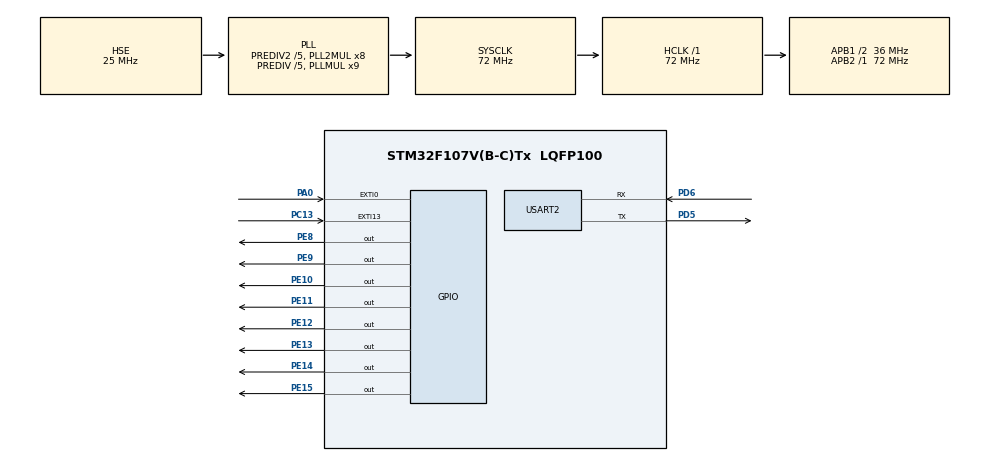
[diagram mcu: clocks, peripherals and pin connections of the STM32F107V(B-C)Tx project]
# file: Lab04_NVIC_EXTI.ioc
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Mcu.Family=STM32F1
Mcu.Name=STM32F107V(B-C)Tx
Mcu.Package=LQFP100
NVIC.EXTI0_IRQn=true\:2\:1\:true\:false\:true\:true
NVIC.EXTI15_10_IRQn=true\:1\:3\:true\:false\:true\:true
NVIC.PriorityGroup=NVIC_PRIORITYGROUP_2
OSC_IN.Mode=HSE-External-Oscillator
OSC_IN.Signal=RCC_OSC_IN
OSC_OUT.Mode=HSE-External-Oscillator
OSC_OUT.Signal=RCC_OSC_OUT
PA0-WKUP.Signal=GPXTI0
PC13-TAMPER-RTC.GPIO_ModeDefaultEXTI=GPIO_MODE_IT_FALLING
PC13-TAMPER-RTC.Signal=GPXTI13
PD5.Mode=Asynchronous
PD5.Signal=USART2_TX
PD6.Mode=Asynchronous
PD6.Signal=USART2_RX
PE10.GPIO_Speed=GPIO_SPEED_FREQ_HIGH
PE10.Signal=GPIO_Output
PE11.GPIO_Speed=GPIO_SPEED_FREQ_HIGH
PE11.Signal=GPIO_Output
PE12.GPIO_Speed=GPIO_SPEED_FREQ_HIGH
PE12.Signal=GPIO_Output
PE13.GPIO_Speed=GPIO_SPEED_FREQ_HIGH
PE13.Signal=GPIO_Output
PE14.GPIO_Speed=GPIO_SPEED_FREQ_HIGH
PE14.Signal=GPIO_Output
PE15.GPIO_Speed=GPIO_SPEED_FREQ_HIGH
PE15.Signal=GPIO_Output
PE8.GPIO_Speed=GPIO_SPEED_FREQ_HIGH
PE8.Signal=GPIO_Output
PE9.GPIO_Speed=GPIO_SPEED_FREQ_HIGH
PE9.Signal=GPIO_Output
ProjectManager.HeapSize=0x200
ProjectManager.StackSize=0x400
ProjectManager.TargetToolchain=MDK-ARM V5
RCC.AHBFreq_Value=72000000
RCC.APB1CLKDivider=RCC_HCLK_DIV2
RCC.APB1Freq_Value=36000000
RCC.APB1TimFreq_Value=72000000
RCC.APB2Freq_Value=72000000
RCC.APB2TimFreq_Value=72000000
RCC.HCLKFreq_Value=72000000
RCC.HSEDivPLL=RCC_HSE_PREDIV_DIV5
RCC.HSE_VALUE=25000000
RCC.PLLMUL=RCC_PLL_MUL9
RCC.PLLSourceVirtual=RCC_PLLSOURCE_HSE
RCC.Prediv1Source=RCC_PREDIV1_SOURCE_PLL2
RCC.Prediv2=RCC_HSE_PREDIV2_DIV5
RCC.SYSCLKFreq_VALUE=72000000
RCC.SYSCLKSource=RCC_SYSCLKSOURCE_PLLCLK
RCC.USBFreq_Value=48000000
USART2.VirtualMode=VM_ASYNC
VP_SYS_VS_ND.Mode=No_Debug
board=Lab04_NVIC_EXTI

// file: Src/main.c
/**
  ******************************************************************************
  * File Name          : main.c
  * Description        : Main program body
  ******************************************************************************
  ** This notice applies to any and all portions of this file
  * that are not between comment pairs USER CODE BEGIN and
  * USER CODE END. Other portions of this file, whether
  * inserted by the user or by software development tools
  * are owned by their respective copyright owners.
  *
  * COPYRIGHT(c) 2018 STMicroelectronics
  *
  * Redistribution and use in source and binary forms, with or without modification,
  * are permitted provided that the following conditions are met:
  *   1. Redistributions of source code must retain the above copyright notice,
  *      this list of conditions and the following disclaimer.
  *   2. Redistributions in binary form must reproduce the above copyright notice,
  *      this list of conditions and the following disclaimer in the documentation
  *      and/or other materials provided with the distribution.
  *   3. Neither the name of STMicroelectronics nor the names of its contributors
  *      may be used to endorse or promote products derived from this software
  *      without specific prior written permission.
  *
  * THIS SOFTWARE IS PROVIDED BY THE COPYRIGHT HOLDERS AND CONTRIBUTORS "AS IS"
  * AND ANY EXPRESS OR IMPLIED WARRANTIES, INCLUDING, BUT NOT LIMITED TO, THE
  * IMPLIED WARRANTIES OF MERCHANTABILITY AND FITNESS FOR A PARTICULAR PURPOSE ARE
  * DISCLAIMED. IN NO EVENT SHALL THE COPYRIGHT HOLDER OR CONTRIBUTORS BE LIABLE
  * FOR ANY DIRECT, INDIRECT, INCIDENTAL, SPECIAL, EXEMPLARY, OR CONSEQUENTIAL
  * DAMAGES (INCLUDING, BUT NOT LIMITED TO, PROCUREMENT OF SUBSTITUTE GOODS OR
  * SERVICES; LOSS OF USE, DATA, OR PROFITS; OR BUSINESS INTERRUPTION) HOWEVER
  * CAUSED AND ON ANY THEORY OF LIABILITY, WHETHER IN CONTRACT, STRICT LIABILITY,
  * OR TORT (INCLUDING NEGLIGENCE OR OTHERWISE) ARISING IN ANY WAY OUT OF THE USE
  * OF THIS SOFTWARE, EVEN IF ADVISED OF THE POSSIBILITY OF SUCH DAMAGE.
  *
  ******************************************************************************
  */

#include "main.h"
#include "stm32f1xx_hal.h"

UART_HandleTypeDef huart2;

/* USER CODE BEGIN PV */
/* Private variables ---------------------------------------------------------*/

/* USER CODE END PV */

void SystemClock_Config(void);
static void MX_GPIO_Init(void);
static void MX_USART2_UART_Init(void);

/* USER CODE BEGIN PFP */
/* Private function prototypes -----------------------------------------------*/

/* USER CODE END PFP */

int main(void)
{

  /* MCU Configuration----------------------------------------------------------*/

  /* Reset of all peripherals, Initializes the Flash interface and the Systick. */
  HAL_Init();

  /* Configure the system clock */
  SystemClock_Config();

  /* Initialize all configured peripherals */
  MX_GPIO_Init();
  MX_USART2_UART_Init();

  /* USER CODE BEGIN 2 */
	GPIOE->ODR = 0x0000;
  /* USER CODE END 2 */

  /* Infinite loop */
  while (1)
  {

  /* USER CODE BEGIN 3 */
	HAL_UART_Transmit(&huart2, (uint8_t*)"x", 1, 100);
	HAL_Delay(300);
  }
  /* USER CODE END 3 */

}

/** System Clock Configuration
*/
void SystemClock_Config(void)
{

  RCC_OscInitTypeDef RCC_OscInitStruct;
  RCC_ClkInitTypeDef RCC_ClkInitStruct;

    /**Initializes the CPU, AHB and APB busses clocks
    */
  RCC_OscInitStruct.OscillatorType = RCC_OSCILLATORTYPE_HSE;
  RCC_OscInitStruct.HSEState = RCC_HSE_ON;
  RCC_OscInitStruct.HSEPredivValue = RCC_HSE_PREDIV_DIV5;
  RCC_OscInitStruct.HSIState = RCC_HSI_ON;
  RCC_OscInitStruct.Prediv1Source = RCC_PREDIV1_SOURCE_PLL2;
  RCC_OscInitStruct.PLL.PLLState = RCC_PLL_ON;
  RCC_OscInitStruct.PLL.PLLSource = RCC_PLLSOURCE_HSE;
  RCC_OscInitStruct.PLL.PLLMUL = RCC_PLL_MUL9;
  RCC_OscInitStruct.PLL2.PLL2State = RCC_PLL2_ON;
  RCC_OscInitStruct.PLL2.PLL2MUL = RCC_PLL2_MUL8;
  RCC_OscInitStruct.PLL2.HSEPrediv2Value = RCC_HSE_PREDIV2_DIV5;
  if (HAL_RCC_OscConfig(&RCC_OscInitStruct) != HAL_OK)
  {
    _Error_Handler(__FILE__, __LINE__);
  }

    /**Initializes the CPU, AHB and APB busses clocks
    */
  RCC_ClkInitStruct.ClockType = RCC_CLOCKTYPE_HCLK|RCC_CLOCKTYPE_SYSCLK
                              |RCC_CLOCKTYPE_PCLK1|RCC_CLOCKTYPE_PCLK2;
  RCC_ClkInitStruct.SYSCLKSource = RCC_SYSCLKSOURCE_PLLCLK;
  RCC_ClkInitStruct.AHBCLKDivider = RCC_SYSCLK_DIV1;
  RCC_ClkInitStruct.APB1CLKDivider = RCC_HCLK_DIV2;
  RCC_ClkInitStruct.APB2CLKDivider = RCC_HCLK_DIV1;

  if (HAL_RCC_ClockConfig(&RCC_ClkInitStruct, FLASH_LATENCY_2) != HAL_OK)
  {
    _Error_Handler(__FILE__, __LINE__);
  }

    /**Configure the Systick interrupt time
    */
  HAL_SYSTICK_Config(HAL_RCC_GetHCLKFreq()/1000);

    /**Configure the Systick
    */
  HAL_SYSTICK_CLKSourceConfig(SYSTICK_CLKSOURCE_HCLK);

    /**Configure the Systick interrupt time
    */
  __HAL_RCC_PLLI2S_ENABLE();

  /* SysTick_IRQn interrupt configuration */
  HAL_NVIC_SetPriority(SysTick_IRQn, 0, 0);
}

/* USART2 init function */
static void MX_USART2_UART_Init(void)
{

  huart2.Instance = USART2;
  huart2.Init.BaudRate = 115200;
  huart2.Init.WordLength = UART_WORDLENGTH_8B;
  huart2.Init.StopBits = UART_STOPBITS_1;
  huart2.Init.Parity = UART_PARITY_NONE;
  huart2.Init.Mode = UART_MODE_TX_RX;
  huart2.Init.HwFlowCtl = UART_HWCONTROL_NONE;
  huart2.Init.OverSampling = UART_OVERSAMPLING_16;
  if (HAL_UART_Init(&huart2) != HAL_OK)
  {
    _Error_Handler(__FILE__, __LINE__);
  }

}

/** Configure pins as
        * Analog
        * Input
        * Output
        * EVENT_OUT
        * EXTI
*/
static void MX_GPIO_Init(void)
{

  GPIO_InitTypeDef GPIO_InitStruct;

  /* GPIO Ports Clock Enable */
  __HAL_RCC_GPIOC_CLK_ENABLE();
  __HAL_RCC_GPIOA_CLK_ENABLE();
  __HAL_RCC_GPIOE_CLK_ENABLE();
  __HAL_RCC_GPIOD_CLK_ENABLE();

  /*Configure GPIO pin Output Level */
  HAL_GPIO_WritePin(GPIOE, GPIO_PIN_8|GPIO_PIN_9|GPIO_PIN_10|GPIO_PIN_11
                          |GPIO_PIN_12|GPIO_PIN_13|GPIO_PIN_14|GPIO_PIN_15, GPIO_PIN_RESET);

  /*Configure GPIO pin : PC13 */
  GPIO_InitStruct.Pin = GPIO_PIN_13;
  GPIO_InitStruct.Mode = GPIO_MODE_IT_FALLING;
  GPIO_InitStruct.Pull = GPIO_NOPULL;
  HAL_GPIO_Init(GPIOC, &GPIO_InitStruct);

  /*Configure GPIO pin : PA0 */
  GPIO_InitStruct.Pin = GPIO_PIN_0;
  GPIO_InitStruct.Mode = GPIO_MODE_IT_RISING;
  GPIO_InitStruct.Pull = GPIO_NOPULL;
  HAL_GPIO_Init(GPIOA, &GPIO_InitStruct);

  /*Configure GPIO pins : PE8 PE9 PE10 PE11
                           PE12 PE13 PE14 PE15 */
  GPIO_InitStruct.Pin = GPIO_PIN_8|GPIO_PIN_9|GPIO_PIN_10|GPIO_PIN_11
                          |GPIO_PIN_12|GPIO_PIN_13|GPIO_PIN_14|GPIO_PIN_15;
  GPIO_InitStruct.Mode = GPIO_MODE_OUTPUT_PP;
  GPIO_InitStruct.Speed = GPIO_SPEED_FREQ_HIGH;
  HAL_GPIO_Init(GPIOE, &GPIO_InitStruct);

  /* EXTI interrupt init*/
  HAL_NVIC_SetPriority(EXTI0_IRQn, 2, 1);
  HAL_NVIC_EnableIRQ(EXTI0_IRQn);

  HAL_NVIC_SetPriority(EXTI15_10_IRQn, 1, 3);
  HAL_NVIC_EnableIRQ(EXTI15_10_IRQn);

}

void _Error_Handler(char * file, int line)
{
  while(1)
  {
  }
}

/************************ (C) COPYRIGHT STMicroelectronics *****END OF FILE****/
